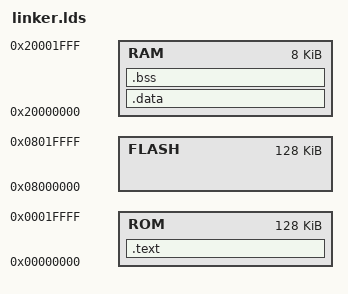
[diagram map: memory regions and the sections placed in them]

ENTRY(_start)

MEMORY
{
        ROM   : ORIGIN = 0x00000000, LENGTH = 128k /* FLASH aliasing */
        FLASH : ORIGIN = 0x08000000, LENGTH = 128k
        RAM   : ORIGIN = 0x20000000, LENGTH = 8k
}

SECTIONS
{
        /**********************************************************************
         *                                                                    *
         **********************************************************************/
        .text :
        {
                _stext = .;
                KEEP(*(.vectors))
                *(.startup)
                *(.text)
                *(.text.*)
                *(.rodata)
                *(.rodata.*)
                . = ALIGN(4);
                PROVIDE(_debug_flag = .);
                BYTE(0x00);
                . = ALIGN(0x10);
                _etext = .;
        } > ROM
        /**********************************************************************
         *                                                                    *
         **********************************************************************/
        .data : AT(_etext)
        {
                _sdata = .;
                *(.data)
                *(.data.*)
                . = ALIGN(0x10);
                _edata = .;
        } > RAM
        /**********************************************************************
         *                                                                    *
         **********************************************************************/
        .bss ADDR(.data) + SIZEOF(.data) (NOLOAD) :
        {
                _sbss = .;
                *(.bss)
                *(.bss.*)
                *(COMMON)
                . = ALIGN(0x10);
                _ebss = .;
        } > RAM
        /**********************************************************************
         *                                                                    *
         **********************************************************************/
        .debug_info     : { *(.debug_info) }
        .debug_abbrev   : { *(.debug_abbrev) }
        .debug_aranges  : { obj/startup.o(.debug_aranges) *(.debug_aranges) }
        .debug_frame    : { *(.debug_frame) }
        .debug_line     : { *(.debug_line) }
        .debug_line_str : { *(.debug_line_str) }
        .debug_loclists : { *(.debug_loclists) }
        .debug_macro    : { *(.debug_macro) }
        .debug_names    : { *(.debug_names) }
        .debug_rnglists : { *(.debug_rnglists) }
        .debug_str      : { *(.debug_str) }
        /**********************************************************************
         *                                                                    *
         **********************************************************************/
        /DISCARD/ :
        {
                *(*)
        }
}

